# ATSAMG55G register map
Vendor: Microchip Technology; Series: SAMG55; File version: 0
CPU: CM4 r0p1, little endian, MPU, FPU, 4 interrupt priority bits
Registers are 32-bit, read-write, reset 0x0 unless marked. A register's access mark holds for its fields unless they carry their own. Offsets are from the block's base; [hi:lo] are bit positions; {n}, {i} and the like mark numbered series.

## WDT — Watchdog Timer
Base 0x400E1450; register names take the prefix WDT_
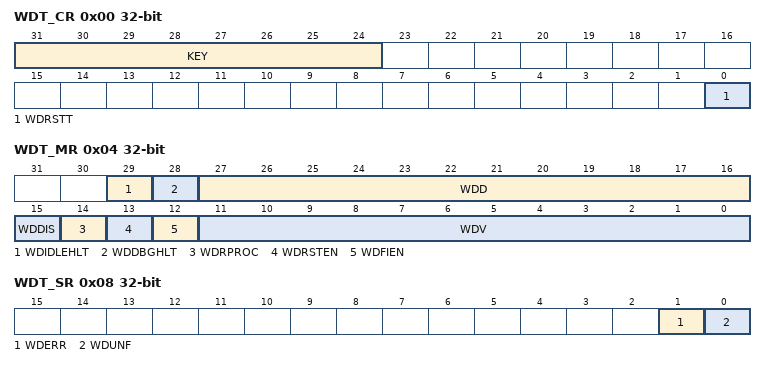
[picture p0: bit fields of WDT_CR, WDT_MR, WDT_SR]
0x00 WDT_CR wo — Control Register
  [31:24] KEY — Password.
    165=PASSWD (Writing any other value in this field aborts the write operation.)
  [0] WDRSTT — Watchdog Restart
0x04 WDT_MR — Mode Register
  [29] WDIDLEHLT — Watchdog Idle Halt
  [28] WDDBGHLT — Watchdog Debug Halt
  [27:16] WDD — Watchdog Delta Value
  [15] WDDIS — Watchdog Disable
  [14] WDRPROC — Watchdog Reset Processor
  [13] WDRSTEN — Watchdog Reset Enable
  [12] WDFIEN — Watchdog Fault Interrupt Enable
  [11:0] WDV — Watchdog Counter Value
0x08 WDT_SR ro — Status Register
  [1] WDERR — Watchdog Error
  [0] WDUNF — Watchdog Underflow

## LOCKBIT
Base 0x00000000; register names take the prefix LOCKBIT_
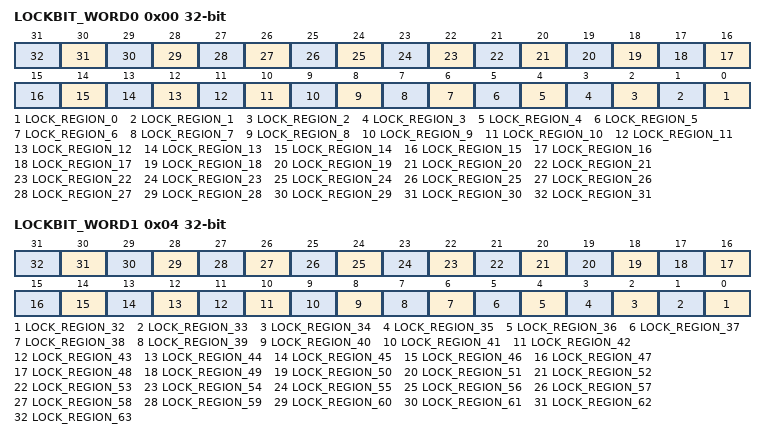
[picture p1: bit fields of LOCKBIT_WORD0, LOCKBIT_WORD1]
0x00 LOCKBIT_WORD0 — Lock Bits Word 0
  [n] LOCK_REGION_{n} (n=0..31)
0x04 LOCKBIT_WORD1 — Lock Bits Word 1
  [n-32] LOCK_REGION_{n} (n=32..63)

## SysTick — System timer
Base 0xE000E010; register names take the prefix SysTick_
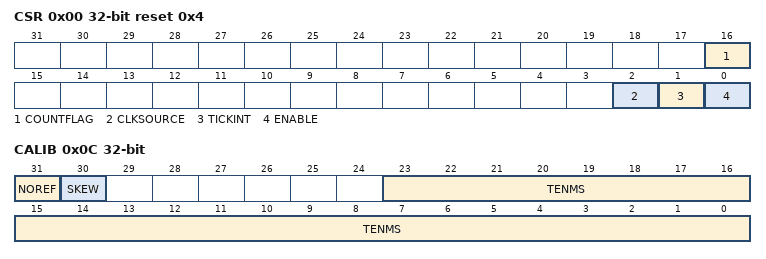
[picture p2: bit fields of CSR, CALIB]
0x00 CSR reset 0x4 — SysTick Control and Status Register
  [16] COUNTFLAG
  [2] CLKSOURCE
    0=external clock; 1=processor clock
  [1] TICKINT
    0=counting down to 0 does not assert the SysTick exception request; 1=counting down to 0 asserts the SysTick exception request
  [0] ENABLE
    0=counter disabled; 1=counter enabled
0x04 RVR — SysTick Reload Value Register
  [23:0] RELOAD — Value to load into the SysTick Current Value Register when the counter reaches 0
0x08 CVR — SysTick Current Value Register
  [23:0] CURRENT — Current value at the time the register is accessed
0x0C CALIB — SysTick Calibration Value Register
  [31] NOREF
    0=The reference clock is provided; 1=The reference clock is not provided
  [30] SKEW
    0=10ms calibration value is exact; 1=10ms calibration value is inexact, because of the clock frequency
  [23:0] TENMS — Reload value to use for 10ms timing

## NVIC — Nested Vectored Interrupt Controller
Base 0xE000E100; register names take the prefix NVIC_
{0x0+4i} NVICISER{i} (i=0..3) — Interrupt Set Enable Register n
  [31:0] SETENA — Interrupt set enable bits
{0x80+4i} NVICICER{i} (i=0..3) — Interrupt Clear Enable Register n
  [31:0] CLRENA — Interrupt clear-enable bits
{0x100+4i} NVICISPR{i} (i=0..3) — Interrupt Set Pending Register n
  [31:0] SETPEND — Interrupt set-pending bits
{0x180+4i} NVICICPR{i} (i=0..3) — Interrupt Clear Pending Register n
  [31:0] CLRPEND — Interrupt clear-pending bits
{0x200+4i} NVICIABR{i} (i=0..3) — Interrupt Active bit Register n
  [31:0] ACTIVE — Interrupt active flags
{0x300+i} NVICIP{i} 8-bit (i=0..105) — Interrupt Priority Register n
  [7:0] PRI{i} — Priority of interrupt {i}
0xE00 NVICSTIR — Software Trigger Interrupt Register
  [8:0] INTID — Interrupt ID of the interrupt to trigger, in the range 0-239. For example, a value of 0x03 specifies interrupt IRQ3.

## MPU — Memory Protection Unit Registers
Base 0xE000ED90; register names take the prefix MPU_
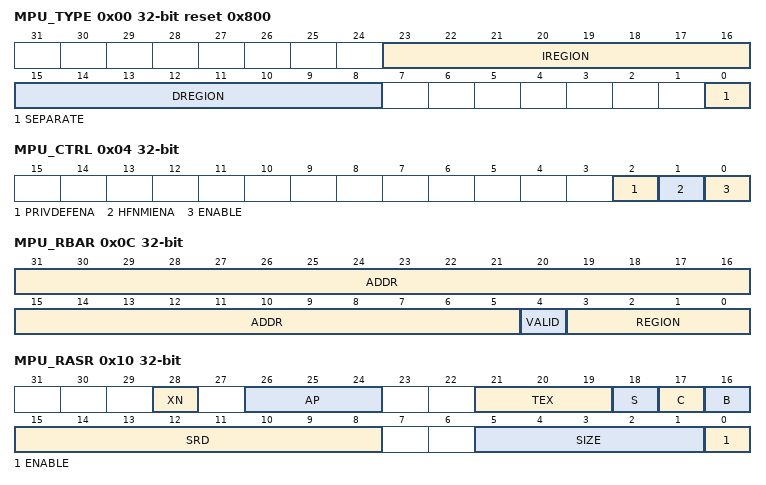
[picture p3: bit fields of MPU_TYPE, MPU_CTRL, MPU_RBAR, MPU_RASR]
0x00 MPU_TYPE ro reset 0x800
  [23:16] IREGION — Indicates the number of supported MPU data regions.
  [15:8] DREGION — Indicates the number of supported MPU instruction regions.
  [0] SEPARATE — Indicates support for unified or separate instruction and date memory maps.
0x04 MPU_CTRL — MPU Control Register
  [2] PRIVDEFENA — Enables privileged software access to the default memory map.
  [1] HFNMIENA — Enables the operation of MPU during hard fault, NMI, and FAULTMASK handlers.
  [0] ENABLE — Enables the MPU
0x08 MPU_RNR — MPU Region Number Register
  [7:0] REGION — Indicates the MPU region referenced by the MPU_RBAR and MPU_RASR registers.
0x0C MPU_RBAR — MPU Region Base Address Register
  [31:5] ADDR — Region base address field.
  [4] VALID — MPU Region Number valid bit.
  [3:0] REGION — MPU region field.
0x10 MPU_RASR — MPU Region Attribute and Size Register
  [28] XN — Instruction access disable bit.
  [26:24] AP — Access permission field.
  [21:19] TEX — MPU access permission attributes.
  [18] S — Shareable bit.
  [17] C — MPU access permission attributes.
  [16] B — MPU access permission attributes.
  [15:8] SRD — Subregion disable bits.
  [5:1] SIZE — Specifies the size of the MPU protection region.
  [0] ENABLE — Region enable bit.

## Notices in the file
Copyright (c) 2017 Microchip Technology Inc.
SPDX-License-Identifier: Apache-2.0
Licensed under the Apache License, Version 2.0 (the "License");
you may not use this file except in compliance with the License.
You may obtain a copy of the License at
http://www.apache.org/licenses/LICENSE-2.0
Unless required by applicable law or agreed to in writing, software
distributed under the License is distributed on an "AS IS" BASIS,
WITHOUT WARRANTIES OR CONDITIONS OF ANY KIND, either express or implied.
See the License for the specific language governing permissions and
limitations under the License.
